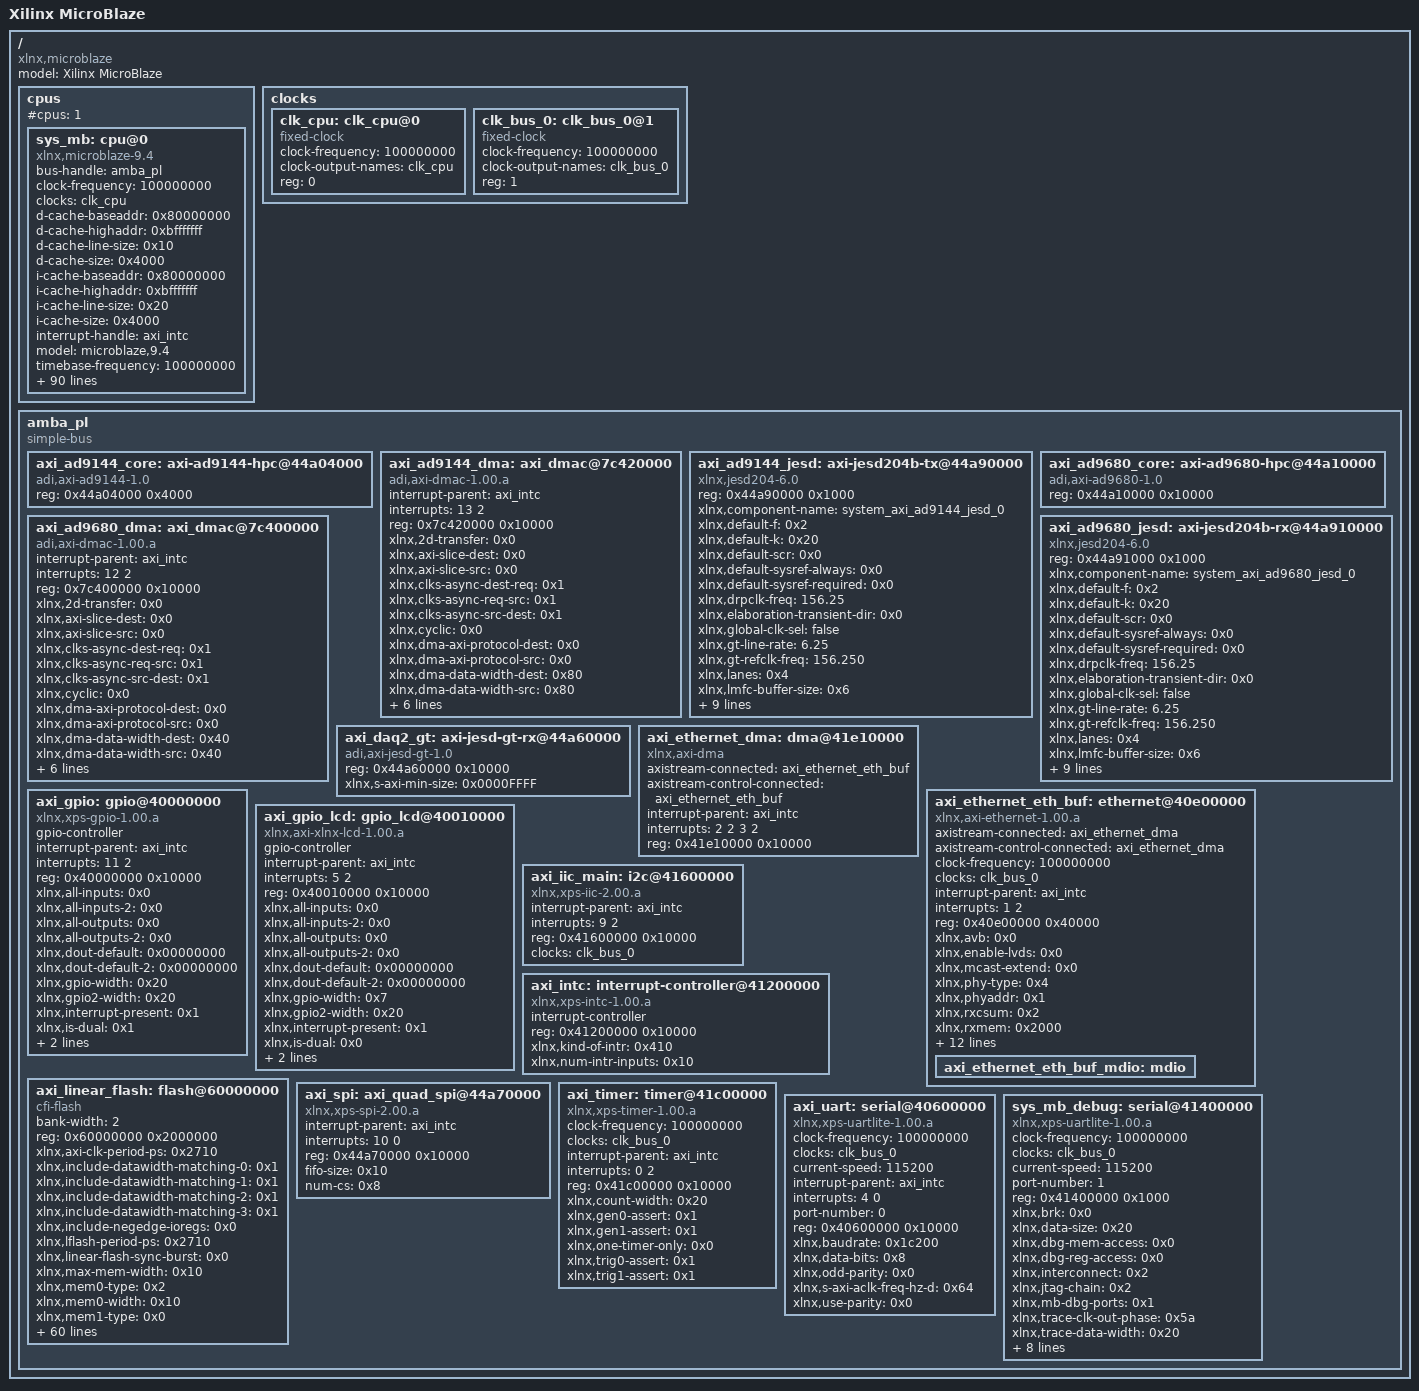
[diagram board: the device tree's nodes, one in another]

/ {
	#address-cells = <1>;
	#size-cells = <1>;
	compatible = "xlnx,microblaze";
	model = "Xilinx MicroBlaze";
	cpus {
		#address-cells = <1>;
		#cpus = <1>;
		#size-cells = <0>;
		sys_mb: cpu@0 {
			bus-handle = <&amba_pl>;
			clock-frequency = <100000000>;
			clocks = <&clk_cpu>;
			compatible = "xlnx,microblaze-9.4";
			d-cache-baseaddr = <0x80000000>;
			d-cache-highaddr = <0xbfffffff>;
			d-cache-line-size = <0x10>;
			d-cache-size = <0x4000>;
			device_type = "cpu";
			i-cache-baseaddr = <0x80000000>;
			i-cache-highaddr = <0xbfffffff>;
			i-cache-line-size = <0x20>;
			i-cache-size = <0x4000>;
			interrupt-handle = <&axi_intc>;
			model = "microblaze,9.4";
			timebase-frequency = <100000000>;
			xlnx,addr-tag-bits = <0x10>;
			xlnx,allow-dcache-wr = <0x1>;
			xlnx,allow-icache-wr = <0x1>;
			xlnx,area-optimized = <0x0>;
			xlnx,async-interrupt = <0x1>;
			xlnx,avoid-primitives = <0x0>;
			xlnx,base-vectors = <0x00000000>;
			xlnx,branch-target-cache-size = <0x0>;
			xlnx,cache-byte-size = <0x4000>;
			xlnx,d-axi = <0x1>;
			xlnx,d-lmb = <0x1>;
			xlnx,data-size = <0x20>;
			xlnx,dcache-addr-tag = <0x10>;
			xlnx,dcache-always-used = <0x1>;
			xlnx,dcache-byte-size = <0x4000>;
			xlnx,dcache-data-width = <0x0>;
			xlnx,dcache-force-tag-lutram = <0x0>;
			xlnx,dcache-line-len = <0x4>;
			xlnx,dcache-use-writeback = <0x0>;
			xlnx,dcache-victims = <0x8>;
			xlnx,debug-counter-width = <0x20>;
			xlnx,debug-enabled = <0x1>;
			xlnx,debug-event-counters = <0x5>;
			xlnx,debug-external-trace = <0x0>;
			xlnx,debug-latency-counters = <0x1>;
			xlnx,debug-profile-size = <0x0>;
			xlnx,debug-trace-size = <0x2000>;
			xlnx,div-zero-exception = <0x1>;
			xlnx,dynamic-bus-sizing = <0x0>;
			xlnx,ecc-use-ce-exception = <0x0>;
			xlnx,edge-is-positive = <0x1>;
			xlnx,enable-discrete-ports = <0x0>;
			xlnx,endianness = <0x1>;
			xlnx,fault-tolerant = <0x0>;
			xlnx,fpu-exception = <0x0>;
			xlnx,freq = <0x5f5e100>;
			xlnx,fsl-exception = <0x0>;
			xlnx,fsl-links = <0x0>;
			xlnx,i-axi = <0x0>;
			xlnx,i-lmb = <0x1>;
			xlnx,icache-always-used = <0x1>;
			xlnx,icache-data-width = <0x0>;
			xlnx,icache-force-tag-lutram = <0x0>;
			xlnx,icache-line-len = <0x8>;
			xlnx,icache-streams = <0x1>;
			xlnx,icache-victims = <0x8>;
			xlnx,ill-opcode-exception = <0x1>;
			xlnx,interconnect = <0x2>;
			xlnx,interrupt-is-edge = <0x0>;
			xlnx,lockstep-select = <0x0>;
			xlnx,lockstep-slave = <0x0>;
			xlnx,mmu-dtlb-size = <0x4>;
			xlnx,mmu-itlb-size = <0x2>;
			xlnx,mmu-privileged-instr = <0x0>;
			xlnx,mmu-tlb-access = <0x3>;
			xlnx,mmu-zones = <0x2>;
			xlnx,num-sync-ff-clk = <0x2>;
			xlnx,num-sync-ff-clk-debug = <0x2>;
			xlnx,num-sync-ff-clk-irq = <0x1>;
			xlnx,num-sync-ff-dbg-clk = <0x1>;
			xlnx,number-of-pc-brk = <0x1>;
			xlnx,number-of-rd-addr-brk = <0x0>;
			xlnx,number-of-wr-addr-brk = <0x0>;
			xlnx,opcode-0x0-illegal = <0x1>;
			xlnx,optimization = <0x0>;
			xlnx,pc-width = <0x20>;
			xlnx,pvr = <0x2>;
			xlnx,pvr-user1 = <0x00>;
			xlnx,pvr-user2 = <0x00000000>;
			xlnx,reset-msr = <0x00000000>;
			xlnx,sco = <0x0>;
			xlnx,trace = <0x0>;
			xlnx,unaligned-exceptions = <0x1>;
			xlnx,use-barrel = <0x1>;
			xlnx,use-branch-target-cache = <0x0>;
			xlnx,use-config-reset = <0x0>;
			xlnx,use-dcache = <0x1>;
			xlnx,use-div = <0x1>;
			xlnx,use-ext-brk = <0x0>;
			xlnx,use-ext-nm-brk = <0x0>;
			xlnx,use-extended-fsl-instr = <0x0>;
			xlnx,use-fpu = <0x0>;
			xlnx,use-hw-mul = <0x2>;
			xlnx,use-icache = <0x1>;
			xlnx,use-interrupt = <0x1>;
			xlnx,use-mmu = <0x3>;
			xlnx,use-msr-instr = <0x1>;
			xlnx,use-pcmp-instr = <0x1>;
			xlnx,use-reorder-instr = <0x1>;
			xlnx,use-stack-protection = <0x0>;
		};
	};
	clocks {
		#address-cells = <1>;
		#size-cells = <0>;
		clk_cpu: clk_cpu@0 {
			#clock-cells = <0>;
			clock-frequency = <100000000>;
			clock-output-names = "clk_cpu";
			compatible = "fixed-clock";
			reg = <0>;
		};
		clk_bus_0: clk_bus_0@1 {
			#clock-cells = <0>;
			clock-frequency = <100000000>;
			clock-output-names = "clk_bus_0";
			compatible = "fixed-clock";
			reg = <1>;
		};
	};
	amba_pl: amba_pl {
		#address-cells = <1>;
		#size-cells = <1>;
		compatible = "simple-bus";
		ranges ;
		axi_ad9144_core: axi-ad9144-hpc@44a04000 {
			compatible = "adi,axi-ad9144-1.0";
			reg = <0x44a04000 0x4000>;
		};
		axi_ad9144_dma: axi_dmac@7c420000 {
			compatible = "adi,axi-dmac-1.00.a";
			interrupt-parent = <&axi_intc>;
			interrupts = <13 2>;
			reg = <0x7c420000 0x10000>;
			xlnx,2d-transfer = <0x0>;
			xlnx,axi-slice-dest = <0x0>;
			xlnx,axi-slice-src = <0x0>;
			xlnx,clks-async-dest-req = <0x1>;
			xlnx,clks-async-req-src = <0x1>;
			xlnx,clks-async-src-dest = <0x1>;
			xlnx,cyclic = <0x0>;
			xlnx,dma-axi-protocol-dest = <0x0>;
			xlnx,dma-axi-protocol-src = <0x0>;
			xlnx,dma-data-width-dest = <0x80>;
			xlnx,dma-data-width-src = <0x80>;
			xlnx,dma-length-width = <0x18>;
			xlnx,dma-type-dest = <0x1>;
			xlnx,dma-type-src = <0x0>;
			xlnx,fifo-size = <0x4>;
			xlnx,max-bytes-per-burst = <0x80>;
			xlnx,sync-transfer-start = <0x0>;
		};
		axi_ad9144_jesd: axi-jesd204b-tx@44a90000 {
			compatible = "xlnx,jesd204-6.0";
			reg = <0x44a90000 0x1000>;
			xlnx,component-name = "system_axi_ad9144_jesd_0";
			xlnx,default-f = <0x2>;
			xlnx,default-k = <0x20>;
			xlnx,default-scr = <0x0>;
			xlnx,default-sysref-always = <0x0>;
			xlnx,default-sysref-required = <0x0>;
			xlnx,drpclk-freq = "156.25";
			xlnx,elaboration-transient-dir = <0x0>;
			xlnx,global-clk-sel = "false";
			xlnx,gt-line-rate = "6.25";
			xlnx,gt-refclk-freq = "156.250";
			xlnx,lanes = <0x4>;
			xlnx,lmfc-buffer-size = <0x6>;
			xlnx,node-is-transmit = <0x1>;
			xlnx,pll-selection = <0x0>;
			xlnx,speedgrade = "-2";
			xlnx,supportlevel = <0x0>;
			xlnx,sysref-sampling-edge = <0x0>;
			xlnx,transceivercontrol = "false";
			xlnx,use-bram = <0x1>;
			xlnx,use-jspat = "false";
			xlnx,use-rpat = "false";
		};
		axi_ad9680_core: axi-ad9680-hpc@44a10000 {
			compatible = "adi,axi-ad9680-1.0";
			reg = <0x44a10000 0x10000>;
		};
		axi_ad9680_dma: axi_dmac@7c400000 {
			compatible = "adi,axi-dmac-1.00.a";
			interrupt-parent = <&axi_intc>;
			interrupts = <12 2>;
			reg = <0x7c400000 0x10000>;
			xlnx,2d-transfer = <0x0>;
			xlnx,axi-slice-dest = <0x0>;
			xlnx,axi-slice-src = <0x0>;
			xlnx,clks-async-dest-req = <0x1>;
			xlnx,clks-async-req-src = <0x1>;
			xlnx,clks-async-src-dest = <0x1>;
			xlnx,cyclic = <0x0>;
			xlnx,dma-axi-protocol-dest = <0x0>;
			xlnx,dma-axi-protocol-src = <0x0>;
			xlnx,dma-data-width-dest = <0x40>;
			xlnx,dma-data-width-src = <0x40>;
			xlnx,dma-length-width = <0x18>;
			xlnx,dma-type-dest = <0x0>;
			xlnx,dma-type-src = <0x1>;
			xlnx,fifo-size = <0x4>;
			xlnx,max-bytes-per-burst = <0x80>;
			xlnx,sync-transfer-start = <0x1>;
		};
		axi_ad9680_jesd: axi-jesd204b-rx@44a910000 {
			compatible = "xlnx,jesd204-6.0";
			reg = <0x44a91000 0x1000>;
			xlnx,component-name = "system_axi_ad9680_jesd_0";
			xlnx,default-f = <0x2>;
			xlnx,default-k = <0x20>;
			xlnx,default-scr = <0x0>;
			xlnx,default-sysref-always = <0x0>;
			xlnx,default-sysref-required = <0x0>;
			xlnx,drpclk-freq = "156.25";
			xlnx,elaboration-transient-dir = <0x0>;
			xlnx,global-clk-sel = "false";
			xlnx,gt-line-rate = "6.25";
			xlnx,gt-refclk-freq = "156.250";
			xlnx,lanes = <0x4>;
			xlnx,lmfc-buffer-size = <0x6>;
			xlnx,node-is-transmit = <0x0>;
			xlnx,pll-selection = <0x0>;
			xlnx,speedgrade = "-2";
			xlnx,supportlevel = <0x0>;
			xlnx,sysref-sampling-edge = <0x0>;
			xlnx,transceivercontrol = "false";
			xlnx,use-bram = <0x1>;
			xlnx,use-jspat = "false";
			xlnx,use-rpat = "false";
		};
		axi_daq2_gt: axi-jesd-gt-rx@44a60000 {
			compatible = "adi,axi-jesd-gt-1.0";
			reg = <0x44a60000 0x10000>;
			xlnx,s-axi-min-size = <0x0000FFFF>;
		};
		axi_ethernet_dma: dma@41e10000 {
			axistream-connected = <&axi_ethernet_eth_buf>;
			axistream-control-connected = <&axi_ethernet_eth_buf>;
			compatible = "xlnx,axi-dma";
			interrupt-parent = <&axi_intc>;
			interrupts = <2 2 3 2>;
			reg = <0x41e10000 0x10000>;
		};
		axi_ethernet_eth_buf: ethernet@40e00000 {
			axistream-connected = <&axi_ethernet_dma>;
			axistream-control-connected = <&axi_ethernet_dma>;
			clock-frequency = <100000000>;
			clocks = <&clk_bus_0>;
			compatible = "xlnx,axi-ethernet-1.00.a";
			device_type = "network";
			interrupt-parent = <&axi_intc>;
			interrupts = <1 2>;
			reg = <0x40e00000 0x40000>;
			xlnx,avb = <0x0>;
			xlnx,enable-lvds = <0x0>;
			xlnx,mcast-extend = <0x0>;
			xlnx,phy-type = <0x4>;
			xlnx,phyaddr = <0x1>;
			xlnx,rxcsum = <0x2>;
			xlnx,rxmem = <0x2000>;
			xlnx,rxvlan-strp = <0x0>;
			xlnx,rxvlan-tag = <0x0>;
			xlnx,rxvlan-tran = <0x0>;
			xlnx,simulation = <0x0>;
			xlnx,stats = <0x1>;
			xlnx,temac-addr-width = <0xc>;
			xlnx,txcsum = <0x2>;
			xlnx,txmem = <0x2000>;
			xlnx,txvlan-strp = <0x0>;
			xlnx,txvlan-tag = <0x0>;
			xlnx,txvlan-tran = <0x0>;
			xlnx,type = <0x1>;
			axi_ethernet_eth_buf_mdio: mdio {
				#address-cells = <1>;
				#size-cells = <0>;
			};
		};
		axi_gpio: gpio@40000000 {
			#gpio-cells = <2>;
			compatible = "xlnx,xps-gpio-1.00.a";
			gpio-controller ;
			interrupt-parent = <&axi_intc>;
			interrupts = <11 2>;
			reg = <0x40000000 0x10000>;
			xlnx,all-inputs = <0x0>;
			xlnx,all-inputs-2 = <0x0>;
			xlnx,all-outputs = <0x0>;
			xlnx,all-outputs-2 = <0x0>;
			xlnx,dout-default = <0x00000000>;
			xlnx,dout-default-2 = <0x00000000>;
			xlnx,gpio-width = <0x20>;
			xlnx,gpio2-width = <0x20>;
			xlnx,interrupt-present = <0x1>;
			xlnx,is-dual = <0x1>;
			xlnx,tri-default = <0xFFFFFFFF>;
			xlnx,tri-default-2 = <0xFFFFFFFF>;
		};
		axi_gpio_lcd: gpio_lcd@40010000 {
			#gpio-cells = <2>;
			compatible = "xlnx,axi-xlnx-lcd-1.00.a";
			gpio-controller ;
			interrupt-parent = <&axi_intc>;
			interrupts = <5 2>;
			reg = <0x40010000 0x10000>;
			xlnx,all-inputs = <0x0>;
			xlnx,all-inputs-2 = <0x0>;
			xlnx,all-outputs = <0x0>;
			xlnx,all-outputs-2 = <0x0>;
			xlnx,dout-default = <0x00000000>;
			xlnx,dout-default-2 = <0x00000000>;
			xlnx,gpio-width = <0x7>;
			xlnx,gpio2-width = <0x20>;
			xlnx,interrupt-present = <0x1>;
			xlnx,is-dual = <0x0>;
			xlnx,tri-default = <0xFFFFFFFF>;
			xlnx,tri-default-2 = <0xFFFFFFFF>;
		};
		axi_iic_main: i2c@41600000 {
			#address-cells = <1>;
			#size-cells = <0>;
			compatible = "xlnx,xps-iic-2.00.a";
			interrupt-parent = <&axi_intc>;
			interrupts = <9 2>;
			reg = <0x41600000 0x10000>;
			clocks = <&clk_bus_0>;
		};
		axi_intc: interrupt-controller@41200000 {
			#interrupt-cells = <2>;
			compatible = "xlnx,xps-intc-1.00.a";
			interrupt-controller ;
			reg = <0x41200000 0x10000>;
			xlnx,kind-of-intr = <0x410>;
			xlnx,num-intr-inputs = <0x10>;
		};
		axi_linear_flash: flash@60000000 {
			bank-width = <2>;
			compatible = "cfi-flash";
			reg = <0x60000000 0x2000000>;
			xlnx,axi-clk-period-ps = <0x2710>;
			xlnx,include-datawidth-matching-0 = <0x1>;
			xlnx,include-datawidth-matching-1 = <0x1>;
			xlnx,include-datawidth-matching-2 = <0x1>;
			xlnx,include-datawidth-matching-3 = <0x1>;
			xlnx,include-negedge-ioregs = <0x0>;
			xlnx,lflash-period-ps = <0x2710>;
			xlnx,linear-flash-sync-burst = <0x0>;
			xlnx,max-mem-width = <0x10>;
			xlnx,mem0-type = <0x2>;
			xlnx,mem0-width = <0x10>;
			xlnx,mem1-type = <0x0>;
			xlnx,mem1-width = <0x10>;
			xlnx,mem2-type = <0x0>;
			xlnx,mem2-width = <0x10>;
			xlnx,mem3-type = <0x0>;
			xlnx,mem3-width = <0x10>;
			xlnx,num-banks-mem = <0x1>;
			xlnx,parity-type-mem-0 = <0x0>;
			xlnx,parity-type-mem-1 = <0x0>;
			xlnx,parity-type-mem-2 = <0x0>;
			xlnx,parity-type-mem-3 = <0x0>;
			xlnx,s-axi-en-reg = <0x0>;
			xlnx,s-axi-mem-addr-width = <0x20>;
			xlnx,s-axi-mem-data-width = <0x20>;
			xlnx,s-axi-mem-id-width = <0x1>;
			xlnx,s-axi-reg-addr-width = <0x5>;
			xlnx,s-axi-reg-data-width = <0x20>;
			xlnx,synch-pipedelay-0 = <0x1>;
			xlnx,synch-pipedelay-1 = <0x1>;
			xlnx,synch-pipedelay-2 = <0x1>;
			xlnx,synch-pipedelay-3 = <0x1>;
			xlnx,tavdv-ps-mem-0 = <0x17700>;
			xlnx,tavdv-ps-mem-1 = <0x3a98>;
			xlnx,tavdv-ps-mem-2 = <0x3a98>;
			xlnx,tavdv-ps-mem-3 = <0x3a98>;
			xlnx,tcedv-ps-mem-0 = <0x17700>;
			xlnx,tcedv-ps-mem-1 = <0x3a98>;
			xlnx,tcedv-ps-mem-2 = <0x3a98>;
			xlnx,tcedv-ps-mem-3 = <0x3a98>;
			xlnx,thzce-ps-mem-0 = <0x1b58>;
			xlnx,thzce-ps-mem-1 = <0x1b58>;
			xlnx,thzce-ps-mem-2 = <0x1b58>;
			xlnx,thzce-ps-mem-3 = <0x1b58>;
			xlnx,thzoe-ps-mem-0 = <0x1b58>;
			xlnx,thzoe-ps-mem-1 = <0x1b58>;
			xlnx,thzoe-ps-mem-2 = <0x1b58>;
			xlnx,thzoe-ps-mem-3 = <0x1b58>;
			xlnx,tlzwe-ps-mem-0 = <0x0>;
			xlnx,tlzwe-ps-mem-1 = <0x0>;
			xlnx,tlzwe-ps-mem-2 = <0x0>;
			xlnx,tlzwe-ps-mem-3 = <0x0>;
			xlnx,tpacc-ps-flash-0 = <0x3a98>;
			xlnx,tpacc-ps-flash-1 = <0x61a8>;
			xlnx,tpacc-ps-flash-2 = <0x61a8>;
			xlnx,tpacc-ps-flash-3 = <0x61a8>;
			xlnx,twc-ps-mem-0 = <0x3a98>;
			xlnx,twc-ps-mem-1 = <0x3a98>;
			xlnx,twc-ps-mem-2 = <0x3a98>;
			xlnx,twc-ps-mem-3 = <0x3a98>;
			xlnx,twp-ps-mem-0 = <0x9c40>;
			xlnx,twp-ps-mem-1 = <0x2ee0>;
			xlnx,twp-ps-mem-2 = <0x2ee0>;
			xlnx,twp-ps-mem-3 = <0x2ee0>;
			xlnx,twph-ps-mem-0 = <0x4e20>;
			xlnx,twph-ps-mem-1 = <0x2ee0>;
			xlnx,twph-ps-mem-2 = <0x2ee0>;
			xlnx,twph-ps-mem-3 = <0x2ee0>;
			xlnx,wr-rec-time-mem-0 = <0x0>;
			xlnx,wr-rec-time-mem-1 = <0x6978>;
			xlnx,wr-rec-time-mem-2 = <0x6978>;
			xlnx,wr-rec-time-mem-3 = <0x6978>;
		};
		axi_spi: axi_quad_spi@44a70000 {
			#address-cells = <1>;
			#size-cells = <0>;
			compatible = "xlnx,xps-spi-2.00.a";
			interrupt-parent = <&axi_intc>;
			interrupts = <10 0>;
			reg = <0x44a70000 0x10000>;
			fifo-size = <0x10>;
			num-cs = <0x8>;
		};
		axi_timer: timer@41c00000 {
			clock-frequency = <100000000>;
			clocks = <&clk_bus_0>;
			compatible = "xlnx,xps-timer-1.00.a";
			interrupt-parent = <&axi_intc>;
			interrupts = <0 2>;
			reg = <0x41c00000 0x10000>;
			xlnx,count-width = <0x20>;
			xlnx,gen0-assert = <0x1>;
			xlnx,gen1-assert = <0x1>;
			xlnx,one-timer-only = <0x0>;
			xlnx,trig0-assert = <0x1>;
			xlnx,trig1-assert = <0x1>;
		};
		axi_uart: serial@40600000 {
			clock-frequency = <100000000>;
			clocks = <&clk_bus_0>;
			compatible = "xlnx,xps-uartlite-1.00.a";
			current-speed = <115200>;
			device_type = "serial";
			interrupt-parent = <&axi_intc>;
			interrupts = <4 0>;
			port-number = <0>;
			reg = <0x40600000 0x10000>;
			xlnx,baudrate = <0x1c200>;
			xlnx,data-bits = <0x8>;
			xlnx,odd-parity = <0x0>;
			xlnx,s-axi-aclk-freq-hz-d = <0x64>;
			xlnx,use-parity = <0x0>;
		};
		sys_mb_debug: serial@41400000 {
			clock-frequency = <100000000>;
			clocks = <&clk_bus_0>;
			compatible = "xlnx,xps-uartlite-1.00.a";
			current-speed = <115200>;
			device_type = "serial";
			port-number = <1>;
			reg = <0x41400000 0x1000>;
			xlnx,brk = <0x0>;
			xlnx,data-size = <0x20>;
			xlnx,dbg-mem-access = <0x0>;
			xlnx,dbg-reg-access = <0x0>;
			xlnx,interconnect = <0x2>;
			xlnx,jtag-chain = <0x2>;
			xlnx,mb-dbg-ports = <0x1>;
			xlnx,trace-clk-out-phase = <0x5a>;
			xlnx,trace-data-width = <0x20>;
			xlnx,trace-output = <0x0>;
			xlnx,trig-in-ports = <0x1>;
			xlnx,trig-out-ports = <0x1>;
			xlnx,use-bscan = <0x0>;
			xlnx,use-config-reset = <0x0>;
			xlnx,use-cross-trigger = <0x0>;
			xlnx,use-uart = <0x1>;
			xlnx,xmtc = <0x0>;
		};
	};
};
